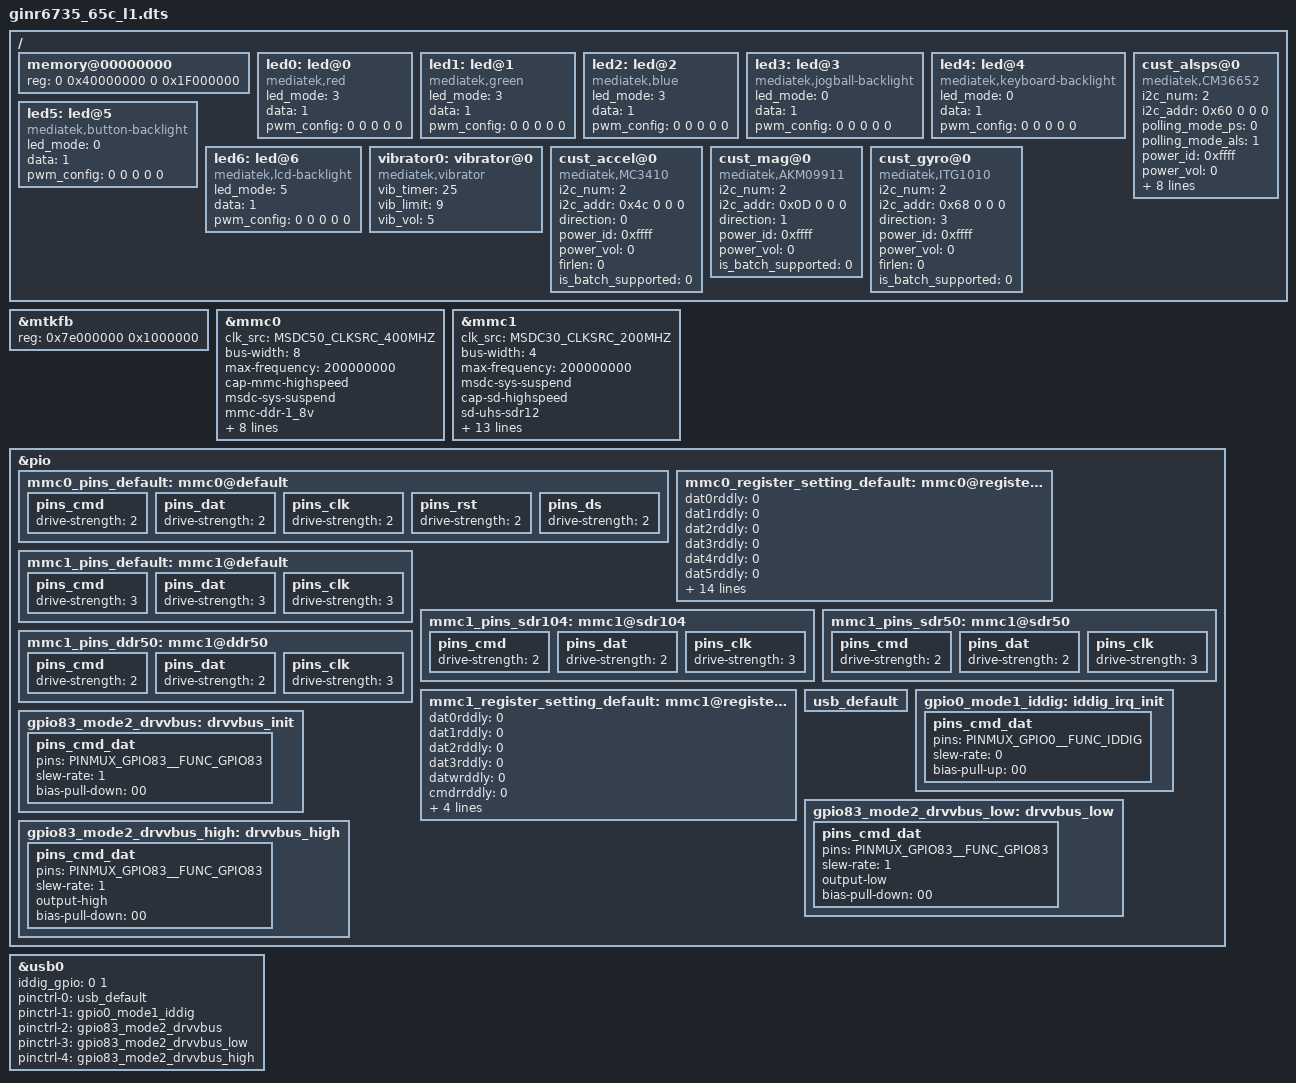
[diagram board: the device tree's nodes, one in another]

/dts-v1/;

#include "mt6735.dtsi"
//#include "cust.dtsi"

/ {
	memory@00000000 {
		device_type = "memory";
		reg = <0 0x40000000 0 0x1F000000>;
	};

//	bus {
//		compatible = "simple-bus";
//		#address-cells = <1>;
//		#size-cells = <1>;
//		ranges = <0 0 0 0xffffffff>;

//		MTKFB@5e200000 {
//			compatible = "mediatek,MTKFB";
//			reg = <0x7E000000 0x1000000>;
//		};
//
//	};

	led0:led@0 {
		compatible = "mediatek,red";
		led_mode = <3>;
		data = <1>;
		pwm_config = <0 0 0 0 0>;
	};
	led1:led@1 {
		compatible = "mediatek,green";
		led_mode = <3>;
		data = <1>;
		pwm_config = <0 0 0 0 0>;
	};
	led2:led@2 {
		compatible = "mediatek,blue";
		led_mode = <3>;
		data = <1>;
		pwm_config = <0 0 0 0 0>;
	};
	led3:led@3 {
		compatible = "mediatek,jogball-backlight";
		led_mode = <0>;
		data = <1>;
		pwm_config = <0 0 0 0 0>;
	};
	led4:led@4 {
		compatible = "mediatek,keyboard-backlight";
		led_mode = <0>;
		data = <1>;
		pwm_config = <0 0 0 0 0>;
	};
	led5:led@5 {
		compatible = "mediatek,button-backlight";
		led_mode = <0>;
		data = <1>;
		pwm_config = <0 0 0 0 0>;
	};
	led6:led@6 {
		compatible = "mediatek,lcd-backlight";
		led_mode = <5>;
		data = <1>;
		pwm_config = <0 0 0 0 0>;
	};
	vibrator0:vibrator@0 {
		compatible = "mediatek,vibrator";
		vib_timer = <25>;
		vib_limit = <9>;
		vib_vol= <5>;
	};
  /*  start sensor */
		cust_accel@0 {
		compatible 				= "mediatek,MC3410";
		i2c_num 				= <2>;
		i2c_addr				= <0x4c 0 0 0>;
		direction 				= <0>;
		power_id 				= <0xffff>;
		power_vol				= <0>;
		firlen 					= <0>;
		is_batch_supported  			= <0>;
  		};
  
		cust_alsps@0 {
		compatible 				= "mediatek,CM36652";
		i2c_num 				= <2>;
		i2c_addr 				= <0x60 0 0 0>;
		polling_mode_ps			= <0>;
		polling_mode_als		= <1>;
		power_id   				= <0xffff>;
		power_vol  				= <0>; 
/* Total has 15 level*/
		als_level  				= <0 328 861 1377 3125 7721 7767 12621 23062 28430 33274 47116 57694 57694 65535>;
/*  Total has 16 range*/
		als_value  				= <0 133 304 502 1004 2005 3058 5005 8008 10010 12000 16000 20000 20000 20000 20000>;
		ps_threshold_high		=  <26>;
		ps_threshold_low		=  <21>;
		is_batch_supported_ps	= <0>;
		is_batch_supported_als	= <0>;
		};
		
  		cust_mag@0 {
		compatible				= "mediatek,AKM09911";
		i2c_num 				= <2>;
		i2c_addr				= <0x0D 0 0 0>;
		direction 				= <1>;
		power_id 				= <0xffff>;
		power_vol				= <0>;
		is_batch_supported  	= <0>;
  		};
		
  		cust_gyro@0 {
		compatible 				= "mediatek,ITG1010";
		i2c_num 				= <2>;
		i2c_addr				= <0x68 0 0 0>;
		direction 				= <3>;
		power_id 				= <0xffff>;
		power_vol				= <0>;
		firlen 					= <0>;
		is_batch_supported  	= <0>;
  		};
  /* end sensor */
};
&mtkfb {
	reg = <0x7e000000 0x1000000>;
};
/* mmc start */
&mmc0 {
		clk_src = /bits/ 8 <MSDC50_CLKSRC_400MHZ>;
		bus-width = <8>;
		max-frequency = <200000000>;
		cap-mmc-highspeed;
		msdc-sys-suspend;
		mmc-ddr-1_8v;
		mmc-hs200-1_8v;
		mmc-hs400-1_8v;
		non-removable;
		pinctl = <&mmc0_pins_default>;
		register_setting = <&mmc0_register_setting_default>;
		host_function = /bits/ 8 <MSDC_EMMC>;
		bootable;
		status = "okay";
};

&mmc1 {
		clk_src = /bits/ 8 <MSDC30_CLKSRC_200MHZ>;
		bus-width = <4>;
		max-frequency = <200000000>;
		msdc-sys-suspend;
		cap-sd-highspeed;
		sd-uhs-sdr12;
		sd-uhs-sdr25;
		sd-uhs-sdr50;
		sd-uhs-sdr104;
		sd-uhs-ddr50;
		pinctl = <&mmc1_pins_default>;
		pinctl_sdr104 = <&mmc1_pins_sdr104>;
		pinctl_sdr50 = <&mmc1_pins_sdr50>;
		pinctl_ddr50 = <&mmc1_pins_ddr50>;
		register_setting = <&mmc1_register_setting_default>;
		host_function = /bits/ 8 <MSDC_SD>;
		cd_level = /bits/ 8 <MSDC_CD_LOW>;
		cd-gpios = <&pio 5 0>;
		status = "okay";
};

&pio {
	mmc0_pins_default: mmc0@default {
		pins_cmd {
			drive-strength = /bits/ 8 <2>;
		};
		pins_dat {
			drive-strength = /bits/ 8 <2>;
		};
		pins_clk {
			drive-strength = /bits/ 8 <2>;
		};
		pins_rst {
			drive-strength = /bits/ 8 <2>;
		};
		pins_ds {
			drive-strength = /bits/ 8 <2>;
		};
	};

	mmc0_register_setting_default: mmc0@register_default {
		dat0rddly      = /bits/ 8 <0>;
		dat1rddly      = /bits/ 8 <0>;
		dat2rddly      = /bits/ 8 <0>;
		dat3rddly      = /bits/ 8 <0>;
		dat4rddly      = /bits/ 8 <0>;
		dat5rddly      = /bits/ 8 <0>;
		dat6rddly      = /bits/ 8 <0>;
		dat7rddly      = /bits/ 8 <0>;
		datwrddly      = /bits/ 8 <0>;
		cmdrrddly      = /bits/ 8 <0>;
		cmdrddly       = /bits/ 8 <0>;
		cmd_edge = /bits/ 8 <MSDC_SMPL_FALLING>;
		rdata_edge = /bits/ 8 <MSDC_SMPL_FALLING>;
		wdata_edge = /bits/ 8 <MSDC_SMPL_FALLING>;

		ett-hs200-cells = <12>;
		ett-hs200-default = <OFFSET_MSDC_PATCH_BIT0	MSDC_PB0_INT_DAT_LATCH_CK_SEL 0x0
			OFFSET_MSDC_PATCH_BIT0	MSDC_PB0_CKGEN_MSDC_DLY_SEL   0x0
			OFFSET_MSDC_PATCH_BIT1	MSDC_PB1_CMD_RSP_TA_CNTR      0x1
			OFFSET_MSDC_IOCON		MSDC_IOCON_RSPL               0x0
			OFFSET_MSDC_PAD_TUNE0	MSDC_PAD_TUNE0_CMDRDLY        0x7
			OFFSET_MSDC_PAD_TUNE0	MSDC_PAD_TUNE0_CMDRRDLY       0xb
			OFFSET_MSDC_PATCH_BIT1		MSDC_PB1_WRDAT_CRCS_TA_CNTR   0x1
			OFFSET_MSDC_PAD_TUNE0	MSDC_PAD_TUNE0_DATWRDLY       0xb
			OFFSET_MSDC_IOCON			MSDC_IOCON_W_D0SPL            0x0
			OFFSET_MSDC_DAT_RDDLY0		MSDC_DAT_RDDLY0_D0            0x7
			OFFSET_MSDC_PAD_TUNE0	MSDC_PAD_TUNE0_DATRRDLY       0x9
			OFFSET_MSDC_IOCON		MSDC_IOCON_R_D_SMPL           0x0>;

		ett-hs400-cells = <8>;
		ett-hs400-default = <OFFSET_MSDC_PATCH_BIT0	MSDC_PB0_INT_DAT_LATCH_CK_SEL	0x0
			OFFSET_MSDC_PATCH_BIT0		MSDC_PB0_CKGEN_MSDC_DLY_SEL		0x0
			OFFSET_EMMC50_PAD_DS_TUNE	MSDC_EMMC50_PAD_DS_TUNE_DLY1	0x2
			OFFSET_EMMC50_PAD_DS_TUNE	MSDC_EMMC50_PAD_DS_TUNE_DLY3	0x10
			OFFSET_MSDC_PATCH_BIT1			MSDC_PB1_CMD_RSP_TA_CNTR	0x1
			OFFSET_MSDC_IOCON		MSDC_IOCON_RSPL				0x0
			OFFSET_MSDC_PAD_TUNE0			MSDC_PAD_TUNE0_CMDRDLY		0x6
			OFFSET_MSDC_PAD_TUNE0		MSDC_PAD_TUNE0_CMDRRDLY		0x6>;
	};

	mmc1_pins_default: mmc1@default {
			pins_cmd {
				drive-strength = /bits/ 8 <3>;
			};
			pins_dat {
				drive-strength = /bits/ 8 <3>;
			};
			pins_clk {
				drive-strength = /bits/ 8 <3>;
			};
	};

	mmc1_pins_sdr104: mmc1@sdr104 {
			pins_cmd {
				drive-strength = /bits/ 8 <2>;
			};
			pins_dat {
				drive-strength = /bits/ 8 <2>;
			};
			pins_clk {
				drive-strength = /bits/ 8 <3>;
			};
	};

	mmc1_pins_sdr50: mmc1@sdr50 {
			pins_cmd {
				drive-strength = /bits/ 8 <2>;
			};
			pins_dat {
				drive-strength = /bits/ 8 <2>;
			};
			pins_clk {
				drive-strength = /bits/ 8 <3>;
			};
	};

	mmc1_pins_ddr50: mmc1@ddr50 {
			pins_cmd {
				drive-strength = /bits/ 8 <2>;
			};
			pins_dat {
				drive-strength = /bits/ 8 <2>;
			};
			pins_clk {
				drive-strength = /bits/ 8 <3>;
			};
	};

	mmc1_register_setting_default: mmc1@register_default {
				dat0rddly      = /bits/ 8 <0>;
				dat1rddly      = /bits/ 8 <0>;
				dat2rddly      = /bits/ 8 <0>;
				dat3rddly      = /bits/ 8 <0>;
				datwrddly      = /bits/ 8 <0>;
				cmdrrddly      = /bits/ 8 <0>;
				cmdrddly       = /bits/ 8 <0>;
				cmd_edge = /bits/ 8 <MSDC_SMPL_FALLING>;
				rdata_edge = /bits/ 8 <MSDC_SMPL_FALLING>;
				wdata_edge = /bits/ 8 <MSDC_SMPL_FALLING>;
	};
};
/* mmc end */
/* USB GPIO Kernal Standardization start */
&pio {
	usb_default: usb_default {
	};

	gpio0_mode1_iddig: iddig_irq_init {
		pins_cmd_dat {
			pins = <PINMUX_GPIO0__FUNC_IDDIG>;
			slew-rate = <0>;
			bias-pull-up = <00>;
		};
	};

	gpio83_mode2_drvvbus: drvvbus_init {
		pins_cmd_dat {
			pins = <PINMUX_GPIO83__FUNC_GPIO83>;
			slew-rate = <1>;
			bias-pull-down = <00>;
		};
	};

	gpio83_mode2_drvvbus_low: drvvbus_low {
		pins_cmd_dat {
			pins = <PINMUX_GPIO83__FUNC_GPIO83>;
			slew-rate = <1>;
			output-low;
			bias-pull-down = <00>;
		};
	};

	gpio83_mode2_drvvbus_high: drvvbus_high {
		pins_cmd_dat {
			pins = <PINMUX_GPIO83__FUNC_GPIO83>;
			slew-rate = <1>;
			output-high;
			bias-pull-down = <00>;
		};
	};
};

&usb0 {
	iddig_gpio = <0 1>;
	pinctrl-names = "usb_default", "iddig_irq_init", "drvvbus_init", "drvvbus_low", "drvvbus_high";
	pinctrl-0 = <&usb_default>;
	pinctrl-1 = <&gpio0_mode1_iddig>;
	pinctrl-2 = <&gpio83_mode2_drvvbus>;
	pinctrl-3 = <&gpio83_mode2_drvvbus_low>;
	pinctrl-4 = <&gpio83_mode2_drvvbus_high>;
	status = "okay";
};
/* USB GPIO Kernal Standardization end */
